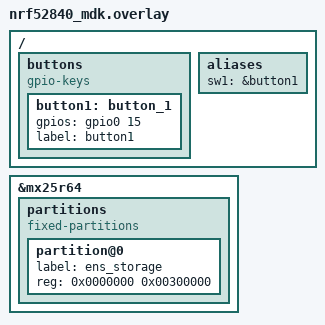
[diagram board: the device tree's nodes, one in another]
/ {
	buttons {
		compatible = "gpio-keys";
		button1: button_1 {
			gpios = <&gpio0 15 (GPIO_PULL_DOWN | GPIO_ACTIVE_HIGH)>;
			label = "button1";
		};
	};
	aliases {
		sw1 = &button1;
	};

};

&mx25r64 {
	partitions {
		compatible = "fixed-partitions";
		#address-cells = <1>;
		#size-cells = <1>;

		partition@0 {
			label = "ens_storage";
			reg = <0x0000000 0x00300000>;
		};
	};
};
